/*---------GLOBAL DEFINITIONS-----------*/
LIN_description_file;
LIN_protocol_version = "2.1";
LIN_language_version = "2.1";
LIN_speed = 19.2 kbps;
/* ----------NODE DEFINITIONS---------- */
Nodes {
   Master:
      BCM, /* Master node name */
      5.0 ms, /* Time base */
      0.1 ms; /* Jitter */
   Slaves:
      RLS;
}
/* ----------SIGNAL DEFINITIONS---------- */
Signals {
   /* Signal_name : Size, Init, Publisher, Subscriber(s) */
   BCM_Status_IGN : 2, 0x0, BCM, RLS;
   BCM_CMD_AutoWiper : 1, 0x0, BCM, RLS;
   BCM_RQ_FrontWash : 1, 0x0, BCM, RLS;
   BCM_ParkPosition : 1, 0x0, BCM, RLS;
   BCM_RainSensitivity : 3, 0x0, BCM, RLS;
   BCM_CMD_AutoLight : 1, 0x0, BCM, RLS;
   BCM_BladesTurningPoint : 1, 0x0, BCM, RLS;
   BCM_RoofStatus : 1, 0x0, BCM, RLS;
   BCM_SPD_Vehicle : 13, 0x0, BCM, RLS;
   BCM_OutsideTemp : 8, 0x0, BCM, RLS;
   RLS_MsgCounter : 4, 0x0, RLS, BCM;
   RLS_RQ_WiperSPD : 2, 0x0, RLS, BCM;
   RLS_RQ_LowBeam : 1, 0x0, RLS, BCM;
   RLS_RQ_PositionLamp : 1, 0x0, RLS, BCM;
   RLS_Fault_Rain : 1, 0x0, RLS, BCM;
   RLS_Fault_Light : 1, 0x0, RLS, BCM;
   RLS_REP_Error : 1, 0x0, RLS, BCM;
   RLS_VOLT_Error : 2, 0x0, RLS, BCM;
   RLS_Humid_Temp_Error : 1, 0x0, RLS, BCM;
   RLS_Brightness_IR_L : 8, 0x0, RLS, BCM;
   RLS_Brightness_FW : 10, 0x0, RLS, BCM;
   RLS_Rain_Intensity : 4, 0x0, RLS, BCM;
   RLS_Brightness_IR_R : 8, 0x0, RLS, BCM;
   RLS_Temperature : 8, 0x0, RLS, BCM;
   RLS_Humid : 8, 0x0, RLS, BCM;
}
/* ----------DIAGNOSTIC SIGNAL DEFINITIONS---------- */
Diagnostic_signals {
   /* MasterReq Reserved Signals */
   MasterReqB0 : 8, 0;
   MasterReqB1 : 8, 0;
   MasterReqB2 : 8, 0;
   MasterReqB3 : 8, 0;
   MasterReqB4 : 8, 0;
   MasterReqB5 : 8, 0;
   MasterReqB6 : 8, 0;
   MasterReqB7 : 8, 0;
   /* SlaveResp Reserved Signals */
   SlaveRespB0 : 8, 0;
   SlaveRespB1 : 8, 0;
   SlaveRespB2 : 8, 0;
   SlaveRespB3 : 8, 0;
   SlaveRespB4 : 8, 0;
   SlaveRespB5 : 8, 0;
   SlaveRespB6 : 8, 0;
   SlaveRespB7 : 8, 0;
}
/* ----------UNCONDITIONAL FRAME DEFINITIONS---------- */
Frames {
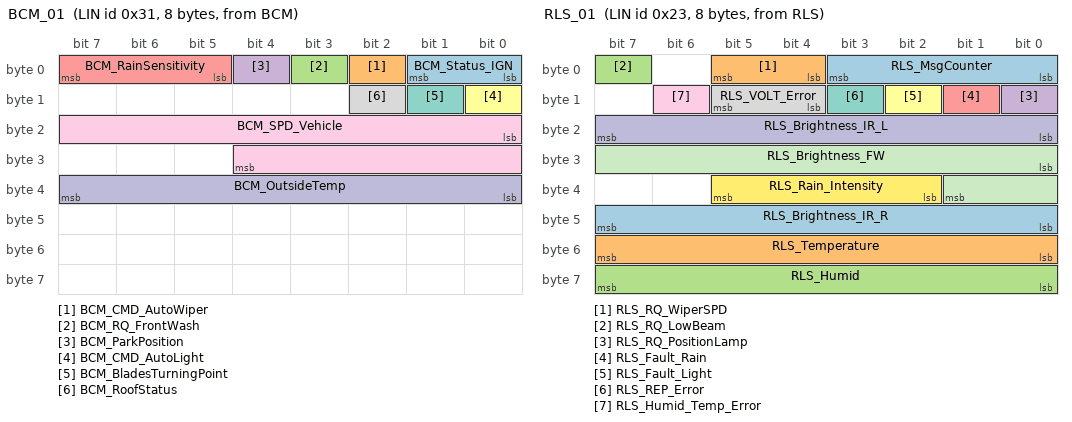
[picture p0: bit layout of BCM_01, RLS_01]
   BCM_01 : 0x31, BCM , 8 {
      BCM_Status_IGN , 0;
      BCM_CMD_AutoWiper , 2;
      BCM_RQ_FrontWash , 3;
      BCM_ParkPosition , 4;
      BCM_RainSensitivity , 5;
      BCM_CMD_AutoLight , 8;
      BCM_BladesTurningPoint, 9;
      BCM_RoofStatus , 10;
      BCM_SPD_Vehicle , 16;
      BCM_OutsideTemp , 32;
   }
   RLS_01 : 0x23, RLS , 8 {
      RLS_MsgCounter , 0;
      RLS_RQ_WiperSPD , 4;
      RLS_RQ_LowBeam , 7;
      RLS_RQ_PositionLamp , 8;
      RLS_Fault_Rain , 9;
      RLS_Fault_Light , 10;
      RLS_REP_Error , 11;
      RLS_VOLT_Error , 12;
      RLS_Humid_Temp_Error, 14;
      RLS_Brightness_IR_L , 16;
      RLS_Brightness_FW , 24;
      RLS_Rain_Intensity , 34;
      RLS_Brightness_IR_R , 40;
      RLS_Temperature , 48;
      RLS_Humid , 56;
   }
}
/* ----------DIAGNOSTIC FRAME DEFINITIONS---------- */
Diagnostic_frames {
   MasterReq : 0x3c {
      MasterReqB0 , 0;
      MasterReqB1 , 8;
      MasterReqB2 , 16;
      MasterReqB3 , 24;
      MasterReqB4 , 32;
      MasterReqB5 , 40;
      MasterReqB6 , 48;
      MasterReqB7 , 56;
   }
   SlaveResp : 0x3d {
      SlaveRespB0 , 0;
      SlaveRespB1 , 8;
      SlaveRespB2 , 16;
      SlaveRespB3 , 24;
      SlaveRespB4 , 32;
      SlaveRespB5 , 40;
      SlaveRespB6 , 48;
      SlaveRespB7 , 56;
   }
}
/* ----------NODE ATTRIBUTE DEFINITIONS---------- */
Node_attributes {
   RLS {
      LIN_protocol = "2.1"; /* Node protocol version */
      configured_NAD = 0x16; /* configured NAD of node (1-125) */
      initial_NAD = 0x16; /* initial NAD of node (1-125) */
      product_id = 0x23, 0x23, 0xff; /* Product id */
      response_error = RLS_REP_Error; /* Response error signal */
      P2_min = 50 ms; /* P2_min */
      ST_min = 20 ms; /* ST_min */
      N_As_timeout = 1000 ms; /* N_As timeout value */
      N_Cr_timeout = 1000 ms; /* N_Cr timeout value */
      configurable_frames {
         RLS_01;
         BCM_01;
      }
   }
}
/* ----------SCHEDULE TABLE DEFINITIONS---------- */
Schedule_tables {
   NormalTable {
      BCM_01 delay 40.0 ms;
      RLS_01 delay 10.0 ms;
   }
   Diagnose {
      MasterReq delay 10.0 ms;
   }
}
